VERSION ""

NS_ :

BS_:

BU_: FLSDR ADAS FDR GW FRSDR RLSDR RRSDR Tester

BO_ 821 ADAS_FrP22_335: 8 ADAS
 SG_ ADAS_Plt_Cfg_FCTASetResp : 29|2@0+ (1,0) [0|3] "" FLSDR

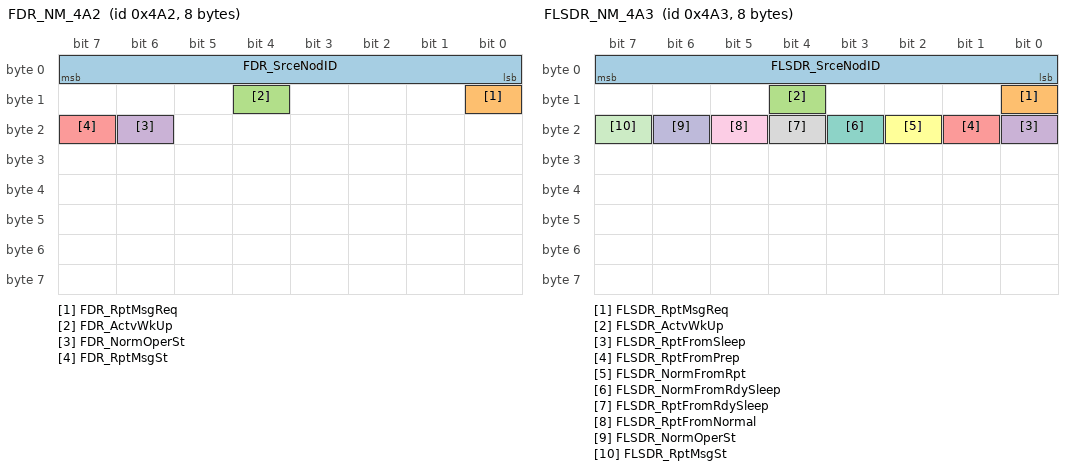
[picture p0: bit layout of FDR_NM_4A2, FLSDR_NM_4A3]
BO_ 1186 FDR_NM_4A2: 8 FDR
 SG_ FDR_SrceNodID : 7|8@0+ (1,0) [0|255] "" FLSDR
 SG_ FDR_RptMsgReq : 8|1@0+ (1,0) [0|1] "" FLSDR
 SG_ FDR_ActvWkUp : 12|1@0+ (1,0) [0|1] "" FLSDR
 SG_ FDR_NormOperSt : 22|1@0+ (1,0) [0|1] "" FLSDR
 SG_ FDR_RptMsgSt : 23|1@0+ (1,0) [0|1] "" FLSDR

BO_ 812 FLSDR_FrP01_32C: 8 FLSDR
 SG_ FLSDR_FCTA_Warng_L : 23|2@0+ (1,0) [0|3] "" ADAS,GW

BO_ 1187 FLSDR_NM_4A3: 8 FLSDR
 SG_ FLSDR_SrceNodID : 7|8@0+ (1,0) [0|255] "" FDR,FRSDR,GW,RLSDR,RRSDR
 SG_ FLSDR_RptMsgReq : 8|1@0+ (1,0) [0|1] "" FDR,FRSDR,GW,RLSDR,RRSDR
 SG_ FLSDR_ActvWkUp : 12|1@0+ (1,0) [0|1] "" FDR,FRSDR,GW,RLSDR,RRSDR
 SG_ FLSDR_RptFromSleep : 16|1@0+ (1,0) [0|1] "" Vector__XXX
 SG_ FLSDR_RptFromPrep : 17|1@0+ (1,0) [0|1] "" Vector__XXX
 SG_ FLSDR_NormFromRpt : 18|1@0+ (1,0) [0|1] "" Vector__XXX
 SG_ FLSDR_NormFromRdySleep : 19|1@0+ (1,0) [0|1] "" Vector__XXX
 SG_ FLSDR_RptFromRdySleep : 20|1@0+ (1,0) [0|1] "" Vector__XXX
 SG_ FLSDR_RptFromNormal : 21|1@0+ (1,0) [0|1] "" Vector__XXX
 SG_ FLSDR_NormOperSt : 22|1@0+ (1,0) [0|1] "" FDR,FRSDR,GW,RLSDR,RRSDR
 SG_ FLSDR_RptMsgSt : 23|1@0+ (1,0) [0|1] "" FDR,FRSDR,GW,RLSDR,RRSDR

BO_ 1482 FLSDR_FrP02_5CA: 8 FLSDR
 SG_ FLSDR_ECUVer : 7|16@0+ (1,0) [0|65535] "" Vector__XXX

BO_ 1730 Diag_DTCInfo_FLSDR: 8 FLSDR
 SG_ Diag_DTCInfo_FLSDR : 7|64@0+ (1,0) [0|1.84467440737096E+019] "" GW,Tester

BO_ 1850 Diag_PhyResp_FLSDR: 8 FLSDR
 SG_ Diag_PhyResp_FLSDR : 7|64@0+ (1,0) [0|1.84467440737096E+019] "" GW,Tester

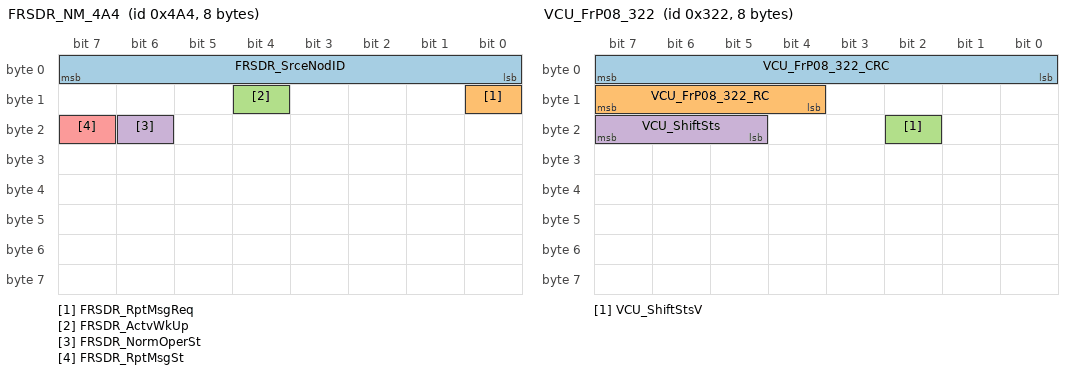
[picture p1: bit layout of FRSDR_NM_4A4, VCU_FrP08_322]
BO_ 1188 FRSDR_NM_4A4: 8 FRSDR
 SG_ FRSDR_SrceNodID : 7|8@0+ (1,0) [0|255] "" FLSDR
 SG_ FRSDR_RptMsgReq : 8|1@0+ (1,0) [0|1] "" FLSDR
 SG_ FRSDR_ActvWkUp : 12|1@0+ (1,0) [0|1] "" FLSDR
 SG_ FRSDR_NormOperSt : 22|1@0+ (1,0) [0|1] "" FLSDR
 SG_ FRSDR_RptMsgSt : 23|1@0+ (1,0) [0|1] "" FLSDR

BO_ 170 VCU_FrP01_AA: 32 GW
 SG_ VCU_FrP01_AA_CRC_1 : 7|8@0+ (1,0) [0|255] "" FLSDR
 SG_ VCU_AccrPedlPosnInv : 11|2@0+ (1,0) [0|3] "" FLSDR
 SG_ VCU_FrP01_AA_RC_1 : 15|4@0+ (1,0) [0|15] "" FLSDR
 SG_ VCU_AccrPedlPosn : 23|8@0+ (0.4,0) [0|102] "" FLSDR
 SG_ VCU_FrP01_AA_CRC_2 : 71|8@0+ (1,0) [0|255] "" FLSDR
 SG_ VCU_FrP01_AA_RC_2 : 79|4@0+ (1,0) [0|15] "" FLSDR
 SG_ VCU_VLCECGPOvrd : 87|1@0+ (1,0) [0|1] "" FLSDR

BO_ 802 VCU_FrP08_322: 8 GW
 SG_ VCU_FrP08_322_CRC : 7|8@0+ (1,0) [0|255] "" FLSDR
 SG_ VCU_FrP08_322_RC : 15|4@0+ (1,0) [0|15] "" FLSDR
 SG_ VCU_ShiftStsV : 18|1@0+ (1,0) [0|1] "" FLSDR
 SG_ VCU_ShiftSts : 23|3@0+ (1,0) [0|7] "" FLSDR

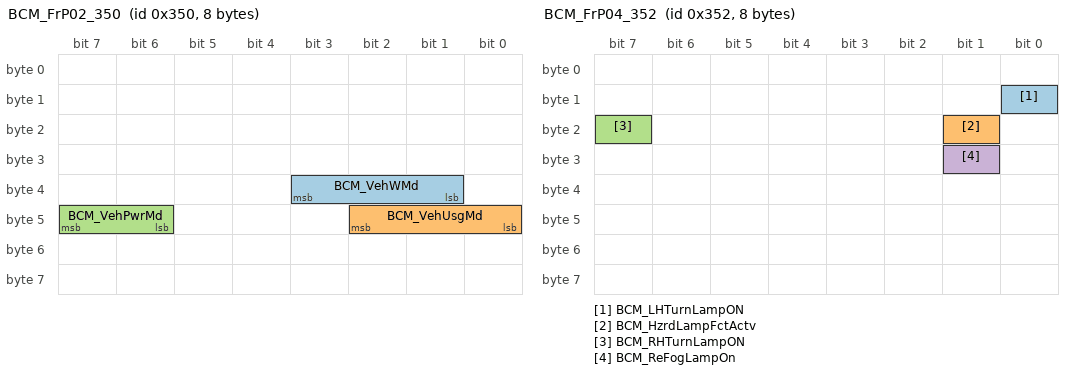
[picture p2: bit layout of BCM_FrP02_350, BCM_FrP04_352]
BO_ 848 BCM_FrP02_350: 8 GW
 SG_ BCM_VehWMd : 35|3@0+ (1,0) [0|7] "" FLSDR
 SG_ BCM_VehUsgMd : 42|3@0+ (1,0) [0|7] "" FLSDR
 SG_ BCM_VehPwrMd : 47|2@0+ (1,0) [0|3] "" FLSDR

BO_ 850 BCM_FrP04_352: 8 GW
 SG_ BCM_LHTurnLampON : 8|1@0+ (1,0) [0|1] "" FLSDR
 SG_ BCM_HzrdLampFctActv : 17|1@0+ (1,0) [0|1] "" FLSDR
 SG_ BCM_RHTurnLampON : 23|1@0+ (1,0) [0|1] "" FLSDR
 SG_ BCM_ReFogLampOn : 25|1@0+ (1,0) [0|1] "" FLSDR

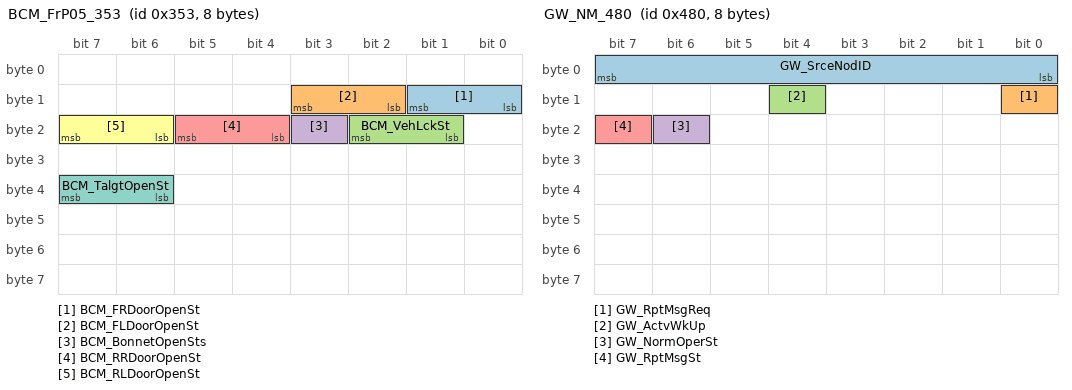
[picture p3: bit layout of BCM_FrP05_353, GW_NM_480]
BO_ 851 BCM_FrP05_353: 8 GW
 SG_ BCM_FRDoorOpenSt : 9|2@0+ (1,0) [0|3] "" FLSDR
 SG_ BCM_FLDoorOpenSt : 11|2@0+ (1,0) [0|3] "" FLSDR
 SG_ BCM_VehLckSt : 18|2@0+ (1,0) [0|3] "" FLSDR
 SG_ BCM_BonnetOpenSts : 19|1@0+ (1,0) [0|1] "" FLSDR
 SG_ BCM_RRDoorOpenSt : 21|2@0+ (1,0) [0|3] "" FLSDR
 SG_ BCM_RLDoorOpenSt : 23|2@0+ (1,0) [0|3] "" FLSDR
 SG_ BCM_TalgtOpenSt : 39|2@0+ (1,0) [0|3] "" FLSDR

BO_ 1152 GW_NM_480: 8 GW
 SG_ GW_SrceNodID : 7|8@0+ (1,0) [0|255] "" FLSDR
 SG_ GW_RptMsgReq : 8|1@0+ (1,0) [0|1] "" FLSDR
 SG_ GW_ActvWkUp : 12|1@0+ (1,0) [0|1] "" FLSDR
 SG_ GW_NormOperSt : 22|1@0+ (1,0) [0|1] "" FLSDR
 SG_ GW_RptMsgSt : 23|1@0+ (1,0) [0|1] "" FLSDR

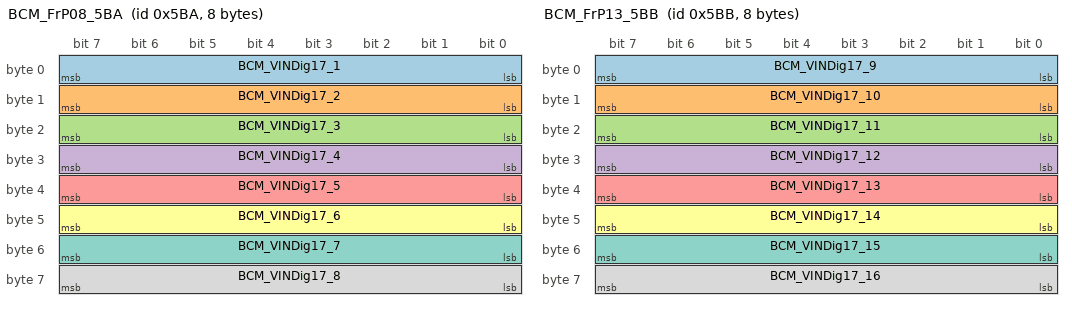
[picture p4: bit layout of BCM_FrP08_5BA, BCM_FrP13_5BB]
BO_ 1466 BCM_FrP08_5BA: 8 GW
 SG_ BCM_VINDig17_1 : 7|8@0+ (1,0) [0|255] "" FLSDR
 SG_ BCM_VINDig17_2 : 15|8@0+ (1,0) [0|255] "" FLSDR
 SG_ BCM_VINDig17_3 : 23|8@0+ (1,0) [0|255] "" FLSDR
 SG_ BCM_VINDig17_4 : 31|8@0+ (1,0) [0|255] "" FLSDR
 SG_ BCM_VINDig17_5 : 39|8@0+ (1,0) [0|255] "" FLSDR
 SG_ BCM_VINDig17_6 : 47|8@0+ (1,0) [0|255] "" FLSDR
 SG_ BCM_VINDig17_7 : 55|8@0+ (1,0) [0|255] "" FLSDR
 SG_ BCM_VINDig17_8 : 63|8@0+ (1,0) [0|255] "" FLSDR

BO_ 1467 BCM_FrP13_5BB: 8 GW
 SG_ BCM_VINDig17_9 : 7|8@0+ (1,0) [0|255] "" FLSDR
 SG_ BCM_VINDig17_10 : 15|8@0+ (1,0) [0|255] "" FLSDR
 SG_ BCM_VINDig17_11 : 23|8@0+ (1,0) [0|255] "" FLSDR
 SG_ BCM_VINDig17_12 : 31|8@0+ (1,0) [0|255] "" FLSDR
 SG_ BCM_VINDig17_13 : 39|8@0+ (1,0) [0|255] "" FLSDR
 SG_ BCM_VINDig17_14 : 47|8@0+ (1,0) [0|255] "" FLSDR
 SG_ BCM_VINDig17_15 : 55|8@0+ (1,0) [0|255] "" FLSDR
 SG_ BCM_VINDig17_16 : 63|8@0+ (1,0) [0|255] "" FLSDR

BO_ 1468 BCM_FrP14_5BC: 8 GW
 SG_ BCM_VINDig17_17 : 7|8@0+ (1,0) [0|255] "" FLSDR

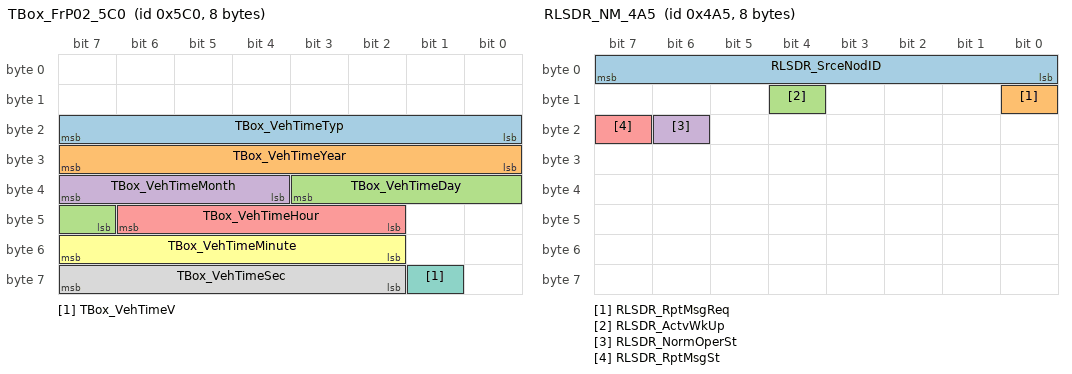
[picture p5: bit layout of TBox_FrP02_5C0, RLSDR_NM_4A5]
BO_ 1472 TBox_FrP02_5C0: 8 GW
 SG_ TBox_VehTimeTyp : 23|8@0+ (1,0) [0|255] "" FLSDR
 SG_ TBox_VehTimeYear : 31|8@0+ (1,2000) [2000|2255] "Year" FLSDR
 SG_ TBox_VehTimeDay : 35|5@0+ (1,0) [0|31] "日" FLSDR
 SG_ TBox_VehTimeMonth : 39|4@0+ (1,0) [0|15] "" FLSDR
 SG_ TBox_VehTimeHour : 46|5@0+ (1,0) [0|31] "h" FLSDR
 SG_ TBox_VehTimeMinute : 55|6@0+ (1,0) [0|63] "Min" FLSDR
 SG_ TBox_VehTimeV : 57|1@0+ (1,0) [0|1] "" FLSDR
 SG_ TBox_VehTimeSec : 63|6@0+ (1,0) [0|63] "S" FLSDR

BO_ 1842 Diag_PhyReq_FLSDR: 8 GW
 SG_ Diag_PhyReq_FLSDR : 7|64@0+ (1,0) [0|1.84467440737096E+019] "" FLSDR

BO_ 2015 Diag_FuncReq_7DF: 8 GW
 SG_ Diag_FuncReq_7DF : 7|64@0+ (1,0) [0|1.84467440737096E+019] "" FLSDR

BO_ 1189 RLSDR_NM_4A5: 8 RLSDR
 SG_ RLSDR_SrceNodID : 7|8@0+ (1,0) [0|255] "" FLSDR
 SG_ RLSDR_RptMsgReq : 8|1@0+ (1,0) [0|1] "" FLSDR
 SG_ RLSDR_ActvWkUp : 12|1@0+ (1,0) [0|1] "" FLSDR
 SG_ RLSDR_NormOperSt : 22|1@0+ (1,0) [0|1] "" FLSDR
 SG_ RLSDR_RptMsgSt : 23|1@0+ (1,0) [0|1] "" FLSDR

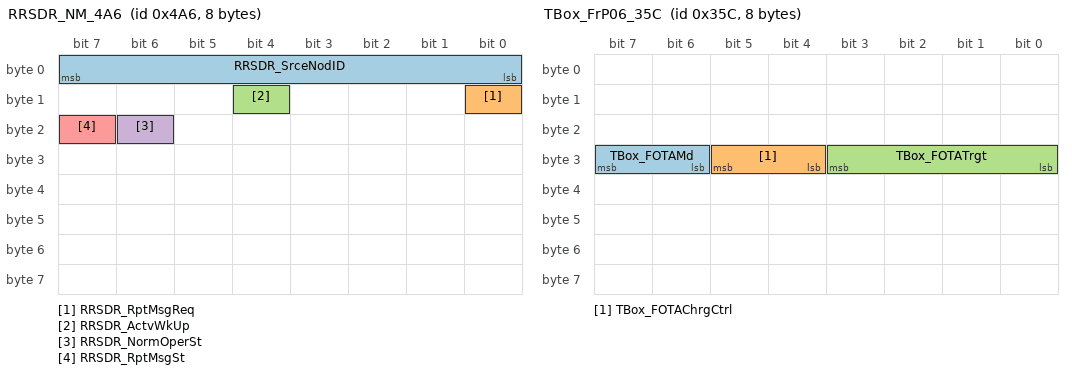
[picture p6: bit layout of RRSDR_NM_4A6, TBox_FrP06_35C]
BO_ 1190 RRSDR_NM_4A6: 8 RRSDR
 SG_ RRSDR_SrceNodID : 7|8@0+ (1,0) [0|255] "" FLSDR
 SG_ RRSDR_RptMsgReq : 8|1@0+ (1,0) [0|1] "" FLSDR
 SG_ RRSDR_ActvWkUp : 12|1@0+ (1,0) [0|1] "" FLSDR
 SG_ RRSDR_NormOperSt : 22|1@0+ (1,0) [0|1] "" FLSDR
 SG_ RRSDR_RptMsgSt : 23|1@0+ (1,0) [0|1] "" FLSDR

BO_ 860 TBox_FrP06_35C: 8 GW
 SG_ TBox_FOTAMd : 31|2@0+ (1,0) [0|3] "" FLSDR
 SG_ TBox_FOTAChrgCtrl : 29|2@0+ (1,0) [0|3] "" FLSDR
 SG_ TBox_FOTATrgt : 27|4@0+ (1,0) [0|15] "" FLSDR

BO_ 1285 VTM_FrP01_505: 8 GW
 SG_ VTM_TralrSts : 23|1@0+ (1,0) [0|1] "" FLSDR

BO_TX_BU_ 1842 : GW,Tester;
BO_TX_BU_ 2015 : GW,Tester;

CM_ BO_ 821 "高阶ADAS发送";
CM_ SG_ 821 ADAS_Plt_Cfg_FCTASetResp "（高阶）前方侧向来车预警开关反馈";
CM_ SG_ 1186 FDR_SrceNodID "Source Node ID";
CM_ SG_ 1186 FDR_RptMsgReq "Repeat Message Request Bit";
CM_ SG_ 1186 FDR_ActvWkUp "Active Wakeup";
CM_ SG_ 1186 FDR_NormOperSt "Normal Operation State";
CM_ SG_ 1186 FDR_RptMsgSt "Repeat Message State";
CM_ SG_ 812 FLSDR_FCTA_Warng_L "（高阶）左侧FCTA报警";
CM_ SG_ 1187 FLSDR_SrceNodID "Source Node ID";
CM_ SG_ 1187 FLSDR_RptMsgReq "Repeat Message Request Bit";
CM_ SG_ 1187 FLSDR_ActvWkUp "Active Wakeup";
CM_ SG_ 1187 FLSDR_RptFromSleep "From  Bus Sleep Mode to Repeat Message State";
CM_ SG_ 1187 FLSDR_RptFromPrep "From Prepare  Bus Sleep Mode to Repeat Message State";
CM_ SG_ 1187 FLSDR_NormFromRpt "From  Repeat Message State to Normal Operation State";
CM_ SG_ 1187 FLSDR_NormFromRdySleep "From  Ready  Sleep  State to Normal  Operation State";
CM_ SG_ 1187 FLSDR_RptFromRdySleep "From Ready Sleep State to Repeat Message State";
CM_ SG_ 1187 FLSDR_RptFromNormal "From  Normal Operation State to Repeat Message State";
CM_ SG_ 1187 FLSDR_NormOperSt "Normal Operation State";
CM_ SG_ 1187 FLSDR_RptMsgSt "Repeat Message State";
CM_ SG_ 1188 FRSDR_SrceNodID "Source Node ID";
CM_ SG_ 1188 FRSDR_RptMsgReq "Repeat Message Request Bit";
CM_ SG_ 1188 FRSDR_ActvWkUp "Active Wakeup";
CM_ SG_ 1188 FRSDR_NormOperSt "Normal Operation State";
CM_ SG_ 1188 FRSDR_RptMsgSt "Repeat Message State";
CM_ SG_ 170 VCU_FrP01_AA_CRC_1 "E2E profile 1 采用CRC-8-SAE J1850，x8+x4 +x3 +x2 +1
Byte1-Byte7进行CRC校验";
CM_ SG_ 170 VCU_AccrPedlPosnInv "Accelerator Pedal Position Invalid";
CM_ SG_ 170 VCU_AccrPedlPosn "Accelerator Pedal Position ";
CM_ SG_ 170 VCU_FrP01_AA_CRC_2 "E2E profile 1 采用CRC-8-SAE J1850，x8+x4 +x3 +x2 +1
Byte9-Byte15进行CRC校验";
CM_ SG_ 170 VCU_VLCECGPOvrd "驾驶员请求扭矩大于ACC请求扭矩";
CM_ SG_ 802 VCU_FrP08_322_CRC "E2E profile 1 采用CRC-8-SAE J1850，x8+x4 +x3 +x2 +1
Byte1-Byte7进行CRC校验";
CM_ SG_ 802 VCU_ShiftStsV "Shift Status Valid";
CM_ SG_ 802 VCU_ShiftSts "Shift Status";
CM_ SG_ 848 BCM_VehWMd "整车工作模式";
CM_ SG_ 848 BCM_VehUsgMd "整车用户模式信号";
CM_ SG_ 848 BCM_VehPwrMd "整车电源模式信号";
CM_ SG_ 850 BCM_LHTurnLampON "左转向灯状态
400ms亮，400ms灭";
CM_ SG_ 850 BCM_HzrdLampFctActv "危险警报状态";
CM_ SG_ 850 BCM_RHTurnLampON "右转向灯状态
400ms亮，400ms灭";
CM_ SG_ 851 BCM_FRDoorOpenSt "右前门状态";
CM_ SG_ 851 BCM_FLDoorOpenSt "左前门状态";
CM_ SG_ 851 BCM_VehLckSt "中控锁状态";
CM_ SG_ 851 BCM_BonnetOpenSts "前机舱盖状态";
CM_ SG_ 851 BCM_RRDoorOpenSt "右后门状态";
CM_ SG_ 851 BCM_RLDoorOpenSt "左后门状态";
CM_ SG_ 851 BCM_TalgtOpenSt "后备箱状态";
CM_ SG_ 1152 GW_SrceNodID "Source Node ID";
CM_ SG_ 1152 GW_RptMsgReq "Repeat Message Request Bit";
CM_ SG_ 1152 GW_ActvWkUp "Active Wakeup";
CM_ SG_ 1152 GW_NormOperSt "Normal Operation State";
CM_ SG_ 1152 GW_RptMsgSt "Repeat Message State";
CM_ SG_ 1466 BCM_VINDig17_1 "车辆VIN码17_1";
CM_ SG_ 1466 BCM_VINDig17_2 "车辆VIN码17_2";
CM_ SG_ 1466 BCM_VINDig17_3 "车辆VIN码17_3";
CM_ SG_ 1466 BCM_VINDig17_4 "车辆VIN码17_4";
CM_ SG_ 1466 BCM_VINDig17_5 "车辆VIN码17_5";
CM_ SG_ 1466 BCM_VINDig17_6 "车辆VIN码17_6";
CM_ SG_ 1466 BCM_VINDig17_7 "车辆VIN码17_7";
CM_ SG_ 1466 BCM_VINDig17_8 "车辆VIN码17_8";
CM_ SG_ 1467 BCM_VINDig17_9 "车辆VIN码17_9";
CM_ SG_ 1467 BCM_VINDig17_10 "车辆VIN码17_10";
CM_ SG_ 1467 BCM_VINDig17_11 "车辆VIN码17_11";
CM_ SG_ 1467 BCM_VINDig17_12 "车辆VIN码17_12";
CM_ SG_ 1467 BCM_VINDig17_13 "车辆VIN码17_13";
CM_ SG_ 1467 BCM_VINDig17_14 "车辆VIN码17_14";
CM_ SG_ 1467 BCM_VINDig17_15 "车辆VIN码17_15";
CM_ SG_ 1467 BCM_VINDig17_16 "车辆VIN码17_16";
CM_ SG_ 1468 BCM_VINDig17_17 "车辆VIN码17_17";
CM_ SG_ 1472 TBox_VehTimeTyp "类型-整车时间";
CM_ SG_ 1472 TBox_VehTimeYear "年-整车时间";
CM_ SG_ 1472 TBox_VehTimeDay "日-整车时间";
CM_ SG_ 1472 TBox_VehTimeMonth "月-整车时间";
CM_ SG_ 1472 TBox_VehTimeHour "时-整车时间";
CM_ SG_ 1472 TBox_VehTimeMinute "分-整车时间";
CM_ SG_ 1472 TBox_VehTimeV "时间有效性";
CM_ SG_ 1472 TBox_VehTimeSec "秒-整车时间";
CM_ SG_ 1189 RLSDR_SrceNodID "Source Node ID";
CM_ SG_ 1189 RLSDR_RptMsgReq "Repeat Message Request Bit";
CM_ SG_ 1189 RLSDR_ActvWkUp "Active Wakeup";
CM_ SG_ 1189 RLSDR_NormOperSt "Normal Operation State";
CM_ SG_ 1189 RLSDR_RptMsgSt "Repeat Message State";
CM_ SG_ 1190 RRSDR_SrceNodID "Source Node ID";
CM_ SG_ 1190 RRSDR_RptMsgReq "Repeat Message Request Bit";
CM_ SG_ 1190 RRSDR_ActvWkUp "Active Wakeup";
CM_ SG_ 1190 RRSDR_NormOperSt "Normal Operation State";
CM_ SG_ 1190 RRSDR_RptMsgSt "Repeat Message State";
CM_ SG_ 860 TBox_FOTAMd "FOTA模式信号";
CM_ SG_ 860 TBox_FOTAChrgCtrl "FOTA补电控制信号";
CM_ SG_ 860 TBox_FOTATrgt "FOTA目标信号";
CM_ SG_ 1285 VTM_TralrSts "拖挂车状态";

BA_DEF_ BO_ "GenMsgSendType" ENUM "Cycle","NoMsgSendType","IfActive","Event","CA","CE";
BA_DEF_ BO_ "GenMsgNrOfRepetition" INT 0 0;
BA_DEF_ BO_ "GenMsgILSupport" ENUM "No","Yes";
BA_DEF_ BO_ "GenMsgCycleTimeFast" INT 0 0;
BA_DEF_ BO_ "GenMsgCycleTime" INT 0 0;
BA_DEF_ BO_ "DiagResponse" ENUM "No","Yes";
BA_DEF_ BO_ "DiagRequest" ENUM "No","Yes";
BA_DEF_ BO_ "NmMessage" ENUM "No","Yes";
BA_DEF_ BO_ "VFrameFormat" ENUM "StandardCAN","ExtendedCAN","reserved","reserved","reserved","reserved","reserved","reserved","reserved","reserved","reserved","reserved","reserved","reserved","StandardCAN_FD","ExtendedCAN_FD";
BA_DEF_ BO_ "CANFD_BRS" ENUM "0","1";
BA_DEF_ SG_ "GenSigStartValue" HEX 0 0;
BA_DEF_ SG_ "GenSigInactiveValue" HEX 0 0;
BA_DEF_ SG_ "GenSigSendType" ENUM "Cycle","OnWrite","OnWriteWithRepetition","OnChange","OnChangeWithRepetition","IfActive","IfActiveWithRepetition","NoSigSendType","vector_leerstring";
BA_DEF_ BU_ "NodeLayerModules" STRING ;
BA_DEF_ BU_ "NmCAN" INT 1 2;
BA_DEF_ BU_ "ILUsed" ENUM "No","Yes";
BA_DEF_ BU_ "CANFD_CANFD_Gateway" ENUM "Yes","No";
BA_DEF_ BU_ "CAN_CANFD_Gateway" ENUM "Yes","No";
BA_DEF_ BU_ "ECUDisplayName" STRING ;
BA_DEF_ BU_ "CAN_CAN_Gateway" ENUM "Yes","No";
BA_DEF_ BU_ "BootloaderNode" ENUM "No","Yes";
BA_DEF_ "NmType" STRING ;
BA_DEF_ "VersionYear" INT 2010 2999;
BA_DEF_ "ProtocolType" STRING ;
BA_DEF_ "NmMessageCount" INT 0 255;
BA_DEF_ "NmBaseAddress" HEX 0 2047;
BA_DEF_ "Manufacturer" STRING ;
BA_DEF_ "DBName" STRING ;
BA_DEF_ "BusType" STRING ;
BA_DEF_ "Baudrate" INT 0 1000000;
BA_DEF_DEF_ "GenMsgSendType" "Cycle";
BA_DEF_DEF_ "GenMsgNrOfRepetition" 0;
BA_DEF_DEF_ "GenMsgILSupport" "Yes";
BA_DEF_DEF_ "GenMsgCycleTimeFast" 0;
BA_DEF_DEF_ "GenMsgCycleTime" 100;
BA_DEF_DEF_ "DiagResponse" "No";
BA_DEF_DEF_ "DiagRequest" "No";
BA_DEF_DEF_ "NmMessage" "No";
BA_DEF_DEF_ "VFrameFormat" "StandardCAN";
BA_DEF_DEF_ "CANFD_BRS" "1";
BA_DEF_DEF_ "GenSigStartValue" 0;
BA_DEF_DEF_ "GenSigInactiveValue" 0;
BA_DEF_DEF_ "GenSigSendType" "Cycle";
BA_DEF_DEF_ "NodeLayerModules" "OSEKNM01.dll,CANoeILNLVector.dll";
BA_DEF_DEF_ "NmCAN" 2;
BA_DEF_DEF_ "ILUsed" "Yes";
BA_DEF_DEF_ "CANFD_CANFD_Gateway" "No";
BA_DEF_DEF_ "CAN_CANFD_Gateway" "No";
BA_DEF_DEF_ "ECUDisplayName" "";
BA_DEF_DEF_ "CAN_CAN_Gateway" "No";
BA_DEF_DEF_ "BootloaderNode" "No";
BA_DEF_DEF_ "NmType" "OSEK";
BA_DEF_DEF_ "VersionYear" 2019;
BA_DEF_DEF_ "ProtocolType" "CAN";
BA_DEF_DEF_ "NmMessageCount" 128;
BA_DEF_DEF_ "NmBaseAddress" 1024;
BA_DEF_DEF_ "Manufacturer" "";
BA_DEF_DEF_ "DBName" "";
BA_DEF_DEF_ "BusType" "";
BA_DEF_DEF_ "Baudrate" 500000;
BA_ "NmMessageCount" 255;
BA_ "BusType" "CAN FD";
BA_ "ProtocolType" "CAN FD";
BA_ "Manufacturer" "JX";
BA_ "DBName" "ADCANFD";
BA_ "NmType" "AUTOSAR";
BA_ "VersionYear" 2023;
BA_ "NodeLayerModules" BU_ FLSDR "CANoeILNLVector.dll";
BA_ "NodeLayerModules" BU_ ADAS "CANoeILNLVector.dll";
BA_ "NodeLayerModules" BU_ FDR "CANoeILNLVector.dll";
BA_ "NodeLayerModules" BU_ GW "CANoeILNLVector.dll";
BA_ "CAN_CAN_Gateway" BU_ GW 0;
BA_ "BootloaderNode" BU_ GW 1;
BA_ "ECUDisplayName" BU_ GW "GW";
BA_ "CANFD_CANFD_Gateway" BU_ GW 0;
BA_ "CAN_CANFD_Gateway" BU_ GW 0;
BA_ "NodeLayerModules" BU_ FRSDR "CANoeILNLVector.dll";
BA_ "NodeLayerModules" BU_ RLSDR "CANoeILNLVector.dll";
BA_ "NodeLayerModules" BU_ RRSDR "CANoeILNLVector.dll";
BA_ "NodeLayerModules" BU_ Tester "CANoeILNLVector.dll";
BA_ "VFrameFormat" BO_ 821 14;
BA_ "GenMsgNrOfRepetition" BO_ 1186 10;
BA_ "GenMsgCycleTime" BO_ 1186 500;
BA_ "NmMessage" BO_ 1186 1;
BA_ "GenMsgCycleTimeFast" BO_ 1186 20;
BA_ "VFrameFormat" BO_ 1186 14;
BA_ "VFrameFormat" BO_ 812 14;
BA_ "GenMsgNrOfRepetition" BO_ 1187 10;
BA_ "GenMsgCycleTime" BO_ 1187 500;
BA_ "NmMessage" BO_ 1187 1;
BA_ "GenMsgCycleTimeFast" BO_ 1187 20;
BA_ "VFrameFormat" BO_ 1187 14;
BA_ "GenMsgCycleTime" BO_ 1482 1000;
BA_ "VFrameFormat" BO_ 1482 14;
BA_ "GenMsgCycleTime" BO_ 1730 0;
BA_ "GenMsgSendType" BO_ 1730 3;
BA_ "VFrameFormat" BO_ 1730 14;
BA_ "GenMsgCycleTime" BO_ 1850 0;
BA_ "DiagResponse" BO_ 1850 1;
BA_ "GenMsgSendType" BO_ 1850 3;
BA_ "VFrameFormat" BO_ 1850 14;
BA_ "GenMsgNrOfRepetition" BO_ 1188 10;
BA_ "GenMsgCycleTime" BO_ 1188 500;
BA_ "NmMessage" BO_ 1188 1;
BA_ "GenMsgCycleTimeFast" BO_ 1188 20;
BA_ "VFrameFormat" BO_ 1188 14;
BA_ "GenMsgCycleTime" BO_ 170 10;
BA_ "VFrameFormat" BO_ 170 14;
BA_ "VFrameFormat" BO_ 802 14;
BA_ "VFrameFormat" BO_ 848 14;
BA_ "VFrameFormat" BO_ 850 14;
BA_ "VFrameFormat" BO_ 851 14;
BA_ "GenMsgNrOfRepetition" BO_ 1152 10;
BA_ "GenMsgCycleTime" BO_ 1152 500;
BA_ "NmMessage" BO_ 1152 1;
BA_ "GenMsgCycleTimeFast" BO_ 1152 20;
BA_ "VFrameFormat" BO_ 1152 14;
BA_ "GenMsgCycleTime" BO_ 1466 1000;
BA_ "VFrameFormat" BO_ 1466 14;
BA_ "GenMsgCycleTime" BO_ 1467 1000;
BA_ "VFrameFormat" BO_ 1467 14;
BA_ "GenMsgCycleTime" BO_ 1468 1000;
BA_ "VFrameFormat" BO_ 1468 14;
BA_ "GenMsgCycleTime" BO_ 1472 1000;
BA_ "VFrameFormat" BO_ 1472 14;
BA_ "GenMsgCycleTime" BO_ 1842 0;
BA_ "DiagRequest" BO_ 1842 1;
BA_ "GenMsgSendType" BO_ 1842 3;
BA_ "VFrameFormat" BO_ 1842 14;
BA_ "GenMsgCycleTime" BO_ 2015 0;
BA_ "GenMsgSendType" BO_ 2015 3;
BA_ "VFrameFormat" BO_ 2015 14;
BA_ "GenMsgNrOfRepetition" BO_ 1189 10;
BA_ "GenMsgCycleTime" BO_ 1189 500;
BA_ "NmMessage" BO_ 1189 1;
BA_ "GenMsgCycleTimeFast" BO_ 1189 20;
BA_ "VFrameFormat" BO_ 1189 14;
BA_ "GenMsgNrOfRepetition" BO_ 1190 10;
BA_ "GenMsgCycleTime" BO_ 1190 500;
BA_ "NmMessage" BO_ 1190 1;
BA_ "GenMsgCycleTimeFast" BO_ 1190 20;
BA_ "VFrameFormat" BO_ 1190 14;
BA_ "VFrameFormat" BO_ 860 14;
BA_ "GenMsgCycleTime" BO_ 1285 200;
BA_ "VFrameFormat" BO_ 1285 14;
BA_ "GenSigSendType" SG_ 1730 Diag_DTCInfo_FLSDR 1;
BA_ "GenSigSendType" SG_ 1850 Diag_PhyResp_FLSDR 1;
BA_ "GenSigStartValue" SG_ 170 VCU_AccrPedlPosnInv 1;
BA_ "GenSigStartValue" SG_ 848 BCM_VehWMd 5;
BA_ "GenSigStartValue" SG_ 848 BCM_VehUsgMd 1;
BA_ "GenSigSendType" SG_ 1842 Diag_PhyReq_FLSDR 1;
BA_ "GenSigSendType" SG_ 2015 Diag_FuncReq_7DF 1;
VAL_ 821 ADAS_Plt_Cfg_FCTASetResp 3 "Reserved" 2 "OFF" 1 "ON" 0 "No Response";
VAL_ 812 FLSDR_FCTA_Warng_L 3 "Reserved" 2 "Warning level 2" 1 "Warning level 1" 0 "No warning";
VAL_ 170 VCU_AccrPedlPosnInv 1 "Invalid" 0 "Normal";
VAL_ 170 VCU_VLCECGPOvrd 1 "Valid" 0 "Invalid";
VAL_ 802 VCU_ShiftStsV 1 "Valid" 0 "Invalid";
VAL_ 802 VCU_ShiftSts 4 "D" 3 "N" 2 "R" 1 "P" 0 "init";
VAL_ 848 BCM_VehWMd 5 "Normal Mode" 4 "Showroom Mode" 3 "Service Mode";
VAL_ 848 BCM_VehUsgMd 7 "Reserve" 6 "Reserve" 5 "Automated Driving" 4 "Normal Driving" 2 "ON" 1 "OFF" 0 "Slee(Reservd)";
VAL_ 848 BCM_VehPwrMd 3 "Crank" 2 "Run" 0 "OFF";
VAL_ 850 BCM_LHTurnLampON 1 "True" 0 "False";
VAL_ 850 BCM_HzrdLampFctActv 1 "True" 0 "False";
VAL_ 850 BCM_RHTurnLampON 1 "True" 0 "False";
VAL_ 850 BCM_ReFogLampOn 1 "True" 0 "False";
VAL_ 851 BCM_FRDoorOpenSt 3 "Full Open" 2 "Ajar（reserve）" 1 "Open(For latch switch can not detect door ajar status)（reserve）" 0 "Closed";
VAL_ 851 BCM_FLDoorOpenSt 3 "Full Open" 2 "Ajar（reserve）" 1 "Open(For latch switch can not detect door ajar status)（reserve）" 0 "Closed";
VAL_ 851 BCM_VehLckSt 3 "Reserved" 2 "All Door Locked" 1 "Drive door Unlocked, other door locked" 0 "All Door Unlocked";
VAL_ 851 BCM_BonnetOpenSts 1 "Open" 0 "Close";
VAL_ 851 BCM_RRDoorOpenSt 3 "Full Open" 2 "Ajar（reserve）" 1 "Open(For latch switch can not detect door ajar status)（reserve）" 0 "Closed";
VAL_ 851 BCM_RLDoorOpenSt 3 "Full Open" 2 "Ajar（reserve）" 1 "Open(For latch switch can not detect door ajar status)（reserve）" 0 "Closed";
VAL_ 851 BCM_TalgtOpenSt 3 "Full Open" 2 "Ajar（reserve)" 1 "Open(For latch switch can not detect door ajar status)（reserve）" 0 "Closed";
VAL_ 1472 TBox_VehTimeTyp 1 "Beijing Time (UTC+8)" 0 "UTC Time";
VAL_ 1472 TBox_VehTimeV 1 "Invalid" 0 "Valid";
VAL_ 860 TBox_FOTAMd 3 "Reserve" 2 "Reserve" 1 "FOTA" 0 "non FOTA";
VAL_ 860 TBox_FOTAChrgCtrl 3 "Reserve" 2 "Reserve" 1 "Charging" 0 "no Charging";
VAL_ 860 TBox_FOTATrgt 15 "Reserve" 14 "Reserve" 13 "Reserve" 12 "Reserve" 11 "Reserve" 10 "Reserve" 9 "Reserve" 8 "Reserve" 7 "Reserve" 6 "Reserve" 5 "Reserve" 4 "Reserve" 3 "Reserve" 2 "GW/BCM/BSK/ICM" 1 "common ECU" 0 "default";
VAL_ 1285 VTM_TralrSts 1 "Trailor Towed" 0 "No Trailor";
